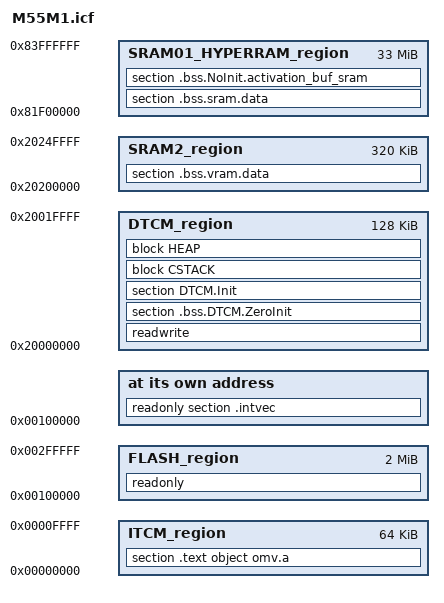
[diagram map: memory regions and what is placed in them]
/*###ICF### Section handled by ICF editor, don't touch! ****/
/*-Editor annotation file-*/
/* IcfEditorFile="$TOOLKIT_DIR$\config\ide\IcfEditor\cortex_v1_0.xml" */
/*-Specials-*/
define symbol __ICFEDIT_intvec_start__ = 0x00100000;
/*-Memory Regions-*/
define symbol __ICFEDIT_region_ITCM_start__   = 0x00000000;
define symbol __ICFEDIT_region_ITCM_end__     = 0x0000FFFF;
define symbol __ICFEDIT_region_FLASH_start__  = 0x00100000;
define symbol __ICFEDIT_region_FLASH_end__    = 0x002FFFFF;
define symbol __ICFEDIT_region_DTCM_start__   = 0x20000000;
define symbol __ICFEDIT_region_DTCM_end__     = 0x2001FFFF;
define symbol __ICFEDIT_region_SRAM2_start__ = 0x20200000;
define symbol __ICFEDIT_region_SRAM2_end__   = 0x2024FFFF;
define symbol __ICFEDIT_region_SRAM01_HYPERRAM_start__   = 0x81F00000;
define symbol __ICFEDIT_region_SRAM01_HYPERRAM_end__     = 0x83FFFFFF;

/*-Sizes-*/
define symbol __ICFEDIT_size_cstack__ = 0x00008000;
define symbol __ICFEDIT_size_heap__   = 0x00014000;
/**** End of ICF editor section. ###ICF###*/


define memory mem with size = 4G;
define region ITCM_region   = mem:[from __ICFEDIT_region_ITCM_start__   to __ICFEDIT_region_ITCM_end__];
define region FLASH_region   = mem:[from __ICFEDIT_region_FLASH_start__   to __ICFEDIT_region_FLASH_end__];
define region SRAM2_region   = mem:[from __ICFEDIT_region_SRAM2_start__   to __ICFEDIT_region_SRAM2_end__];
define region DTCM_region   = mem:[from __ICFEDIT_region_DTCM_start__   to __ICFEDIT_region_DTCM_end__];
define region SRAM01_HYPERRAM_region   = mem:[from __ICFEDIT_region_SRAM01_HYPERRAM_start__   to __ICFEDIT_region_SRAM01_HYPERRAM_end__];

define block CSTACK    with alignment = 8, size = __ICFEDIT_size_cstack__   { };
define block HEAP      with alignment = 8, size = __ICFEDIT_size_heap__     { };

initialize by copy { readwrite, section .text object omv.a, section DTCM.Init };

do not initialize  { section .noinit, section .bss.sram.data, section .bss.vram.data, section .bss.NoInit.activation_buf_sram};

place at address mem:__ICFEDIT_intvec_start__ { readonly section .intvec };

place in FLASH_region   { readonly };
place in ITCM_region   { section .text object omv.a };
place in DTCM_region   { readwrite, section .bss.DTCM.ZeroInit, section DTCM.Init,
                        block CSTACK, block HEAP };
place in SRAM2_region   { section .bss.vram.data };
place in SRAM01_HYPERRAM_region   { section .bss.sram.data, section .bss.NoInit.activation_buf_sram };

